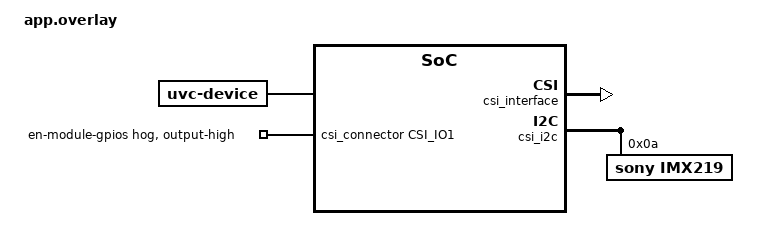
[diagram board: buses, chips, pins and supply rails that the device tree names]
/*
 * Copyright (c) 2025 tinyVision.ai Inc.
 *
 * SPDX-License-Identifier: Apache-2.0
 */


#include <zephyr/dt-bindings/gpio/raspberrypi-csi-connector.h>
#include <zephyr/dt-bindings/video/video-interfaces.h>


/ {
	uvc: uvc {
		compatible = "zephyr,uvc-device";
	};

	chosen {
		zephyr,camera = &csi_interface;
	};

	imx219_input_clock: imx219-input-clock {
		compatible = "fixed-clock";
		clock-frequency = <24000000>;
		#clock-cells = <0>;
	};
};



&csi_interface {
	status = "okay";
};

&csi_ep_in {
	remote-endpoint-label = "imx219_ep_out";
	bus-type = <VIDEO_BUS_TYPE_CSI2_DPHY>;
	data-lanes = <1 2>;
};


&csi_i2c {
	imx219: camera@a {
		compatible = "sony,imx219";
		clocks =  <&imx219_input_clock>;
		reg = <0xa>;


		port {
			imx219_ep_out: endpoint {
				remote-endpoint-label = "csi_ep_in";
				bus-type = <VIDEO_BUS_TYPE_CSI2_DPHY>;
				data-lanes = <1 2>;
			};
		};
	};
};

&csi_connector {
	/*Power on Camera*/
	en-module-gpios  {
		gpio-hog;
		gpios = <CSI_IO1 GPIO_ACTIVE_HIGH>;
		output-high;
	};
};
